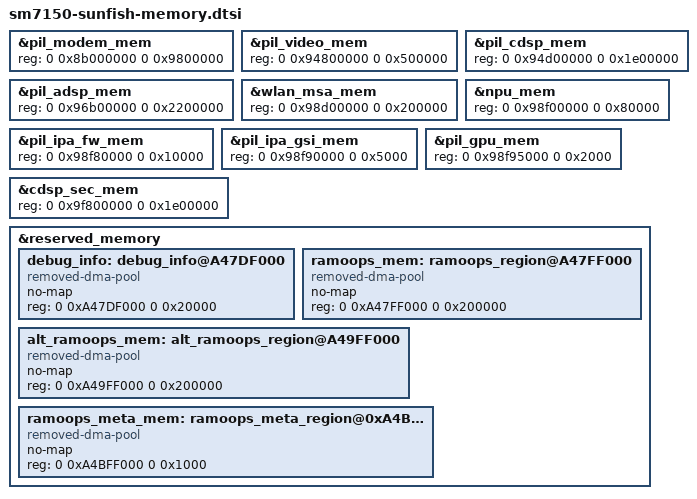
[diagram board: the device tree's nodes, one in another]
/* Copyright (c) 2017-2018, The Linux Foundation. All rights reserved.
 *
 * This program is free software; you can redistribute it and/or modify
 * it under the terms of the GNU General Public License version 2 and
 * only version 2 as published by the Free Software Foundation.
 *
 * This program is distributed in the hope that it will be useful,
 * but WITHOUT ANY WARRANTY; without even the implied warranty of
 * MERCHANTABILITY or FITNESS FOR A PARTICULAR PURPOSE.  See the
 * GNU General Public License for more details.
 */
/* S5 memory includes go here */

&pil_modem_mem {
	reg = <0 0x8b000000 0 0x9800000>;
};
&pil_video_mem {
	reg = <0 0x94800000 0 0x500000>;
};
&pil_cdsp_mem {
	reg = <0 0x94d00000 0 0x1e00000>;
};
&pil_adsp_mem {
	reg = <0 0x96b00000 0 0x2200000>;
};
&wlan_msa_mem {
	reg = <0 0x98d00000 0 0x200000>;
};
&npu_mem {
	reg = <0 0x98f00000 0 0x80000>;
};
&pil_ipa_fw_mem {
	reg = <0 0x98f80000 0 0x10000>;
};
&pil_ipa_gsi_mem {
	reg = <0 0x98f90000 0 0x5000>;
};
&pil_gpu_mem {
	reg = <0 0x98f95000 0 0x2000>;
};
&cdsp_sec_mem {
	reg = <0 0x9f800000 0 0x1e00000>;
};
&reserved_memory {
	debug_info: debug_info@A47DF000 {
		compatible = "removed-dma-pool";
		no-map;
		reg = <0 0xA47DF000 0 0x20000>;
	};

	ramoops_mem: ramoops_region@A47FF000 {
		compatible = "removed-dma-pool";
		no-map;
		reg = <0 0xA47FF000 0 0x200000>;
	};

	alt_ramoops_mem: alt_ramoops_region@A49FF000 {
		compatible = "removed-dma-pool";
		no-map;
		reg = <0 0xA49FF000 0 0x200000>;
	};

	ramoops_meta_mem: ramoops_meta_region@0xA4BFF000 {
		compatible = "removed-dma-pool";
		no-map;
		reg = <0 0xA4BFF000 0 0x1000>;
	};
};
